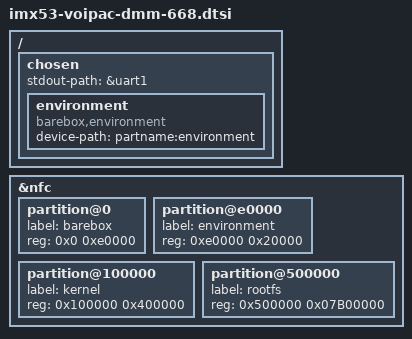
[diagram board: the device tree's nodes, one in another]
/ {
	chosen {
		stdout-path = &uart1;

		environment {
			compatible = "barebox,environment";
			device-path = &nfc, "partname:environment";
		};
	};
};

&nfc {
	#address-cells = <1>;
	#size-cells = <1>;

	partition@0 {
		label = "barebox";
		reg = <0x0 0xe0000>;
	};

	partition@e0000 {
		label = "environment";
		reg = <0xe0000 0x20000>;
	};

	partition@100000 {
		label = "kernel";
		reg = <0x100000 0x400000>;
	};

	partition@500000 {
		label = "rootfs";
		reg = <0x500000 0x07B00000>;
	};
};
